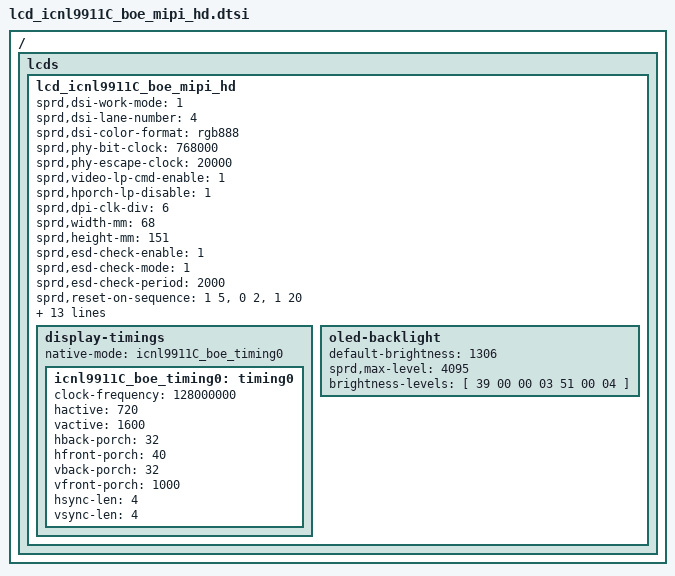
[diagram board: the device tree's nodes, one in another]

/*
 * R61350 Truly LCD config dtsi file for spreadtrum
 *
 * Copyright (C) 2018, Spreadtrum Communications Inc.
 *
 * SPDX-License-Identifier: (GPL-2.0+ OR MIT)
 */

/ {
	fragment {
		target-path = "/";
		__overlay__ {
			lcds {
				lcd_icnl9911C_boe_mipi_hd: lcd_icnl9911C_boe_mipi_hd {

					sprd,dsi-work-mode = <1>; /* video burst mode*/
					sprd,dsi-lane-number = <4>;
					sprd,dsi-color-format = "rgb888";

					sprd,phy-bit-clock = <768000>;	/* kbps */
					sprd,phy-escape-clock = <20000>;/* kHz */

					sprd,video-lp-cmd-enable = <1>;
					sprd,hporch-lp-disable = <1>;
					sprd,dpi-clk-div = <6>;

					sprd,width-mm = <68>;
					sprd,height-mm = <151>;

					sprd,esd-check-enable = <1>;
					sprd,esd-check-mode = <1>;
					sprd,esd-check-period = <2000>;
					/* sprd,esd-check-register = <0x0A>; */
					/* sprd,esd-check-value = <0x9C>; */

					sprd,reset-on-sequence = <1 5>, <0 2>, <1 20>;
					sprd,reset-off-sequence = <1 5>;

					sprd,use-dcs-write;
					sprd,initial-command = [
						39 00 00 03 F0 5A 59
						39 00 00 03 F1 A5 A6
						39 00 00 21 B0 89 88 87 86 02 03 04 05 33 33 33 33 18 01 01 60 01 01 0F 85 04 03 02 01 02 03 04 00 00 00 00 00
						39 00 00 21 B1 53 42 85 81 4A 00 00 60 00 00 04 08 54 00 00 00 44 40 02 01 40 02 01 40 02 01 40 02 01 00 00 00
						39 00 00 12 B2 54 C4 82 05 40 02 01 40 02 01 05 05 54 0C 0C 0D 0B
						39 00 00 21 B3 02 0D 08 0D 08 26 26 91 A2 33 44 00 26 00 18 01 02 08 20 30 0E 09 42 20 00 20 40 08 09 22 33 00
						39 00 00 1D B4 43 1D E3 00 04 06 1C 22 10 12 0C 0E 43 43 43 43 43 43 43 43 43 43 FF FF FC 00 00 00
						39 00 00 1D B5 43 1D E3 00 05 07 1C 22 11 13 0D 0F 43 43 43 43 43 43 43 43 43 43 FF FF FC 00 00 00
						39 00 00 19 B8 00 00 00 00 00 00 00 00 00 00 00 00 00 00 00 00 00 00 00 00 00 00 00 00
						39 00 00 0E BB 01 05 09 11 0D 19 1D 55 25 69 00 21 25
						39 00 00 0F BC 00 00 00 00 02 20 FF 00 03 33 01 73 33 00
						39 00 00 0B BD E9 02 4F CF 72 A4 08 44 AE 15
						39 00 00 0B BE 7D 82 32 5A 0C 77 43 07 0E 0E
						39 00 00 09 BF 07 25 07 25 7F 00 11 04
						39 00 00 0A C0 10 FF FF FF FF FF 00 FF 00
						39 00 00 14 C1 C0 20 20 96 04 28 20 04 2A 40 36 00 07 CF FF FF C0 00 C0
						15 00 00 02 C2 00
						39 00 00 0A C3 06 00 FF 00 FF 00 00 81 01
						39 00 00 0B C4 84 01 2B 41 00 3C 00 03 03 2E
						39 00 00 0C C5 03 1C C0 C0 40 10 42 44 08 0A 14
						39 00 00 0B C6 87 A0 2A 29 29 00 64 37 08 04
						39 00 00 17 C7 FA D5 B9 A3 7B 5C 2B 7D 43 13 E4 AE 03 D4 B5 88 6F 49 1A 7F E4 00
						39 00 00 17 C8 FA D5 B9 A3 7B 5C 2B 7D 43 13 E4 AE 03 D4 B5 88 6F 49 1A 7F E4 00
						39 00 00 07 C9 43 00 1F FF 3F 03
						15 00 00 02 CB 00
						39 00 00 09 D0 80 0D FF 0F 61 0B 08 0C
						39 00 00 0E D2 42 0C 30 01 80 26 04 00 00 C3 00 00 00
						39 00 00 05 FE FF FF FF 50
						39 00 00 1B E0 30 00 80 88 11 3F 22 62 DF A0 04 CC 01 FF F6 FF F0 FD FF FD F8 F5 FC FC FD FF
						39 00 00 18 E1 EF FE FE FE FE EE F0 20 33 FF 00 00 6A 90 C0 0D 6A F0 3E FF 00 07 D0
						39 00 00 03 F1 5A 59
						39 00 00 03 F0 A5 A6
						15 00 00 02 35 00
						39 00 00 03 51 0F FF
						15 00 00 02 53 24
						15 00 00 02 55 00
						05 78 00 01 11
						05 14 00 01 29
						15 00 00 02 26 01
						];

					sprd,sleep-in-command = [
						15 00 00 02 26 08
						05 14 00 01 28
						05 78 00 01 10
						];

					sprd,sleep-out-command = [
						05 78 00 01 11
						05 14 00 01 29
						15 00 00 02 26 01
						];

					sprd,cabc-off-command = [
						23 00 00 02 55 00
						];
					sprd,cabc-ui-command = [
						23 00 00 02 55 01
						];
					sprd,cabc-still-image-command = [
						23 00 00 02 55 02
						];
					sprd,cabc-video-command = [
						23 00 00 02 55 03
						];


					display-timings {
						native-mode = <&icnl9911C_boe_timing0>;

						icnl9911C_boe_timing0: timing0 {
							clock-frequency = <128000000>;
							hactive = <720>;
							vactive = <1600>;
							hback-porch = <32>;
							hfront-porch = <40>;
							vback-porch = <32>;
							vfront-porch = <1000>;
							hsync-len = <4>;
							vsync-len = <4>;
						};
					};

					oled-backlight {
						default-brightness = <1306>;
						sprd,max-level = <4095>;
						brightness-levels = [
            		    	39 00 00 03 51 00 04
						];
					};
				};
			};
		};
	};
};
